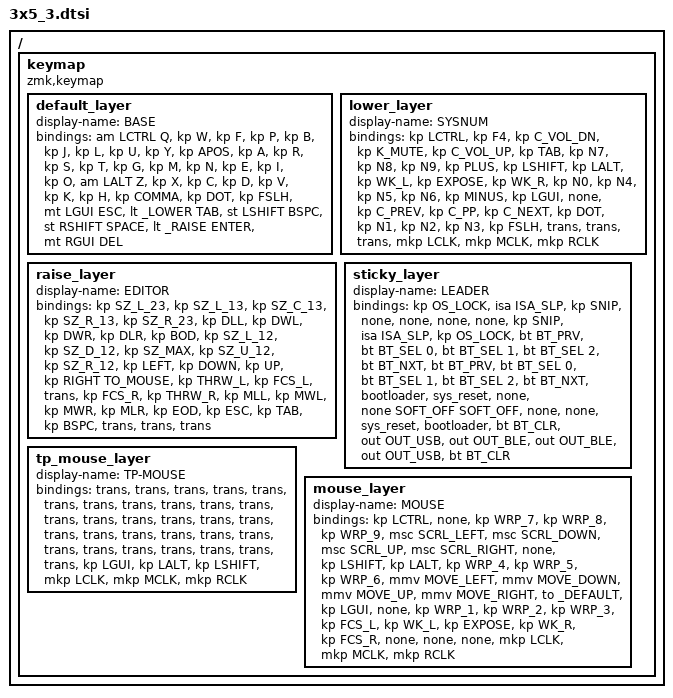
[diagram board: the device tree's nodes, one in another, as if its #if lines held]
#include <behaviors.dtsi>
#include <dt-bindings/zmk/keys.h>
#include <dt-bindings/zmk/bt.h>
#include <dt-bindings/zmk/outputs.h>

#include <behaviors/insomnia.dtsi>
#include <dt-bindings/zmk/insomnia.h>

// define layers
#define _DEFAULT 0  // Colemak Dhm
#define _LOWER 1
#define _RAISE 2
#define _STICKY 3
#define _TPMOUSE 4

// conditionally include mouse keys
// TODO: also make LCLK, MCLK and RCLK in the lower layer safe when mouse keys are not used
#ifdef MOUSE_KEYS
    #include "mouse-keys.dtsi"
    #define _MOUSE 5
    #define TO_MOUSE &to _MOUSE
#else
    #define TO_MOUSE &none
#endif

// safe alias for soft off, even if not enabled
#ifdef USE_SOFT_OFF
    #define SOFT_OFF &soft_off
#else
    #define SOFT_OFF &none
#endif

#include "hold-tap-settings.dtsi"
#include "extra-keycodes.dtsi"
#include "3x5-combos.dtsi"

/ {
    keymap {
        compatible = "zmk,keymap";

        default_layer {
            display-name = "BASE";
// -----------------------------------------------------------------------------------------
//      |  Q  |  W  |  F  |  P  |  B  |            |  J  |  L  |  U  |  Y  |  '  |
//      |  A  |  R  |  S  |  T  |  G  |            |  M  |  N  |  E  |  I  |  O  |
//      |  Z  |  X  |  C  |  D  |  V  |            |  K  |  H  |  ,  |  .  |  /  |
//           taps   | ESC | TAB | BSP |            | SPC | ENT | DEL |
//           holds  | GUI | LWR | SFT |            | SFT | RSE | GUI |
            bindings = <
    &am LCTRL Q &kp W &kp F &kp P &kp B             &kp J &kp L  &kp U     &kp Y   &kp APOS
    &kp A       &kp R &kp S &kp T &kp G             &kp M &kp N  &kp E     &kp I   &kp O
    &am LALT Z  &kp X &kp C &kp D &kp V             &kp K &kp H  &kp COMMA &kp DOT &kp FSLH
    &mt LGUI ESC &lt _LOWER TAB &st LSHIFT BSPC     &st RSHIFT SPACE &lt _RAISE ENTER &mt RGUI DEL
            >;
        };

        lower_layer {
            display-name = "SYSNUM";
            bindings = <
   &kp LCTRL  &kp F4   &kp C_VOL_DN  &kp K_MUTE  &kp C_VOL_UP     &kp TAB  &kp N7  &kp N8  &kp N9  &kp PLUS
   &kp LSHIFT &kp LALT &kp WK_L      &kp EXPOSE  &kp WK_R         &kp N0   &kp N4  &kp N5  &kp N6  &kp MINUS
   &kp LGUI   &none    &kp C_PREV    &kp C_PP    &kp C_NEXT       &kp DOT  &kp N1  &kp N2  &kp N3  &kp FSLH
                                &trans  &trans  &trans            &mkp LCLK  &mkp MCLK &mkp RCLK
            >;
        };

        raise_layer {
            display-name = "EDITOR";
            bindings = <
   &kp SZ_L_23 &kp SZ_L_13 &kp SZ_C_13 &kp SZ_R_13 &kp SZ_R_23      &kp DLL  &kp DWL  &kp DWR &kp DLR   &kp BOD
   &kp SZ_L_12 &kp SZ_D_12 &kp SZ_MAX  &kp SZ_U_12 &kp SZ_R_12      &kp LEFT &kp DOWN &kp UP  &kp RIGHT TO_MOUSE
   &kp THRW_L  &kp FCS_L   &trans      &kp FCS_R   &kp THRW_R       &kp MLL  &kp MWL  &kp MWR &kp MLR   &kp EOD
                           &kp ESC &kp TAB  &kp BSPC   &trans   &trans    &trans
            >;
        };

        sticky_layer {
            display-name = "LEADER";
            bindings = <
    &kp OS_LOCK &isa ISA_SLP &kp SNIP    &none        &none       &none      &none       &kp SNIP     &isa ISA_SLP &kp OS_LOCK
    &bt BT_PRV &bt BT_SEL 0 &bt BT_SEL 1 &bt BT_SEL 2 &bt BT_NXT  &bt BT_PRV &bt BT_SEL 0 &bt BT_SEL 1 &bt BT_SEL 2 &bt BT_NXT
    &bootloader  &sys_reset &none        &none        SOFT_OFF    SOFT_OFF   &none        &none        &sys_reset   &bootloader
                    &bt BT_CLR &out OUT_USB  &out OUT_BLE          &out OUT_BLE &out OUT_USB &bt BT_CLR
            >;
        };

        tp_mouse_layer {
            display-name = "TP-MOUSE";
            bindings = <
    &trans &trans &trans &trans &trans          &trans &trans &trans &trans &trans
    &trans &trans &trans &trans &trans          &trans &trans &trans &trans &trans
    &trans &trans &trans &trans &trans          &trans &trans &trans &trans &trans
                &kp LGUI &kp LALT &kp LSHIFT    &mkp LCLK  &mkp MCLK &mkp RCLK
            >;
        };

    #ifdef MOUSE_KEYS
        mouse_layer {
            display-name = "MOUSE";
            bindings = <
    &kp LCTRL  &none     &kp WRP_7 &kp WRP_8 &kp WRP_9      &msc SCRL_LEFT  &msc SCRL_DOWN  &msc SCRL_UP  &msc SCRL_RIGHT  &none
    &kp LSHIFT &kp LALT  &kp WRP_4 &kp WRP_5 &kp WRP_6      &mmv MOVE_LEFT  &mmv MOVE_DOWN  &mmv MOVE_UP  &mmv MOVE_RIGHT  &to _DEFAULT
    &kp LGUI   &none     &kp WRP_1 &kp WRP_2 &kp WRP_3      &kp FCS_L  &kp WK_L  &kp EXPOSE  &kp WK_R  &kp FCS_R
                         &none     &none     &none          &mkp LCLK  &mkp MCLK &mkp RCLK
            >;
        };
    #endif
    };
};

